# CY8C5868AXI_LP035 register map
File version: 0.1
CY8C58LP
Registers are 32-bit, read-write, no defined reset value unless marked. A register's access mark holds for its fields unless they carry their own. Offsets are from the block's base; lines under a group give offsets from that group; [hi:lo] are bit positions; {n}, {i} and the like mark numbered series; 'fields as' and 'values as' point back to an identical list; <NAME> marks a mode.

## Memory map
0x00000000 b1_critical_timer
0x00000000 b2_critical_timer
0x00000000 LED_Driver2
0x00000000 LED_Driver1
0x00000000 tach_critical_timer
0x00000000 c1_critical_timer
0x00000000 b3_critical_timer
0x00000000 CAN
0x00000000 CAN_Timer

## b1_critical_timer
Base 0x00000000
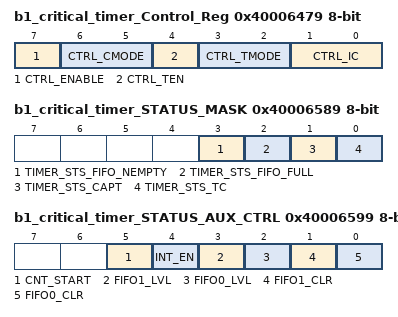
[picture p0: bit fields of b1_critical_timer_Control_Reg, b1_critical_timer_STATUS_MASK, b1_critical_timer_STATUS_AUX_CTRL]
0x40006479 b1_critical_timer_Control_Reg 8-bit — UDB Control Register - Assigned Control Register Value
  [7] CTRL_ENABLE — Enable the Timer
  [6:5] CTRL_CMODE — Capture Mode
  [4] CTRL_TEN — Trigger Enable Bit
  [3:2] CTRL_TMODE — Trigger Mode
  [1:0] CTRL_IC — Interrupt Count
0x40006508 b1_critical_timer_COUNTER 16-bit — UDB.A0 - Current Down Counter Value
0x40006528 b1_critical_timer_PERIOD 16-bit — UDB.D0 - Assigned Period
0x40006589 b1_critical_timer_STATUS_MASK 8-bit — UDB Status bits Interrupt Mask Enable Register
  [3] TIMER_STS_FIFO_NEMPTY ro — FIFO Empty status
  [2] TIMER_STS_FIFO_FULL ro — FIFO Full Status
  [1] TIMER_STS_CAPT ro — Enables the Interrupt on Capture
  [0] TIMER_STS_TC ro — Enables the Interrupt on TC
0x40006599 b1_critical_timer_STATUS_AUX_CTRL 8-bit — UDB Auxilliary Control Register
  [5] CNT_START — FIFO0 clear
    0=E_CNT_START0 (Disable counter); 1=E_CNT_START1 (Enable counter)
  [4] INT_EN
    0=E_INT_EN0 (Interrupt disabled); 1=E_INT_EN1 (Interrupt enabled)
  [3] FIFO1_LVL — FIFO level
    0=E_FIFO_LVL_0 (FIFO LVL: input mode: FIFO not full; output mode: FIFO not empty); 1=E_FIFO_LVL_1 (FIFO LVL: input mode: FIFO at least 1/2 empty; output mode: FIFO at least 1/2 full)
  [2] FIFO0_LVL — FIFO level
    values as FIFO1_LVL
  [1] FIFO1_CLR — FIFO1 clear
    0=E_FIFO_CLR_0 (Normal FIFO operation); 1=E_FIFO_CLR_1 (Clear FIFO state)
  [0] FIFO0_CLR — FIFO0 clear
    values as FIFO1_CLR

## b2_critical_timer
Base 0x00000000
0x4000650A b2_critical_timer_COUNTER 16-bit — UDB.A0 - Current Down Counter Value
0x4000652A b2_critical_timer_PERIOD 16-bit — UDB.D0 - Assigned Period
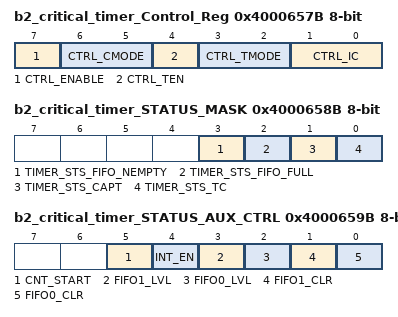
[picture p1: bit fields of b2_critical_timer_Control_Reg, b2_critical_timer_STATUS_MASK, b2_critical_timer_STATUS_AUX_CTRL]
0x4000657B b2_critical_timer_Control_Reg 8-bit — UDB Control Register - Assigned Control Register Value
  [7] CTRL_ENABLE — Enable the Timer
  [6:5] CTRL_CMODE — Capture Mode
  [4] CTRL_TEN — Trigger Enable Bit
  [3:2] CTRL_TMODE — Trigger Mode
  [1:0] CTRL_IC — Interrupt Count
0x4000658B b2_critical_timer_STATUS_MASK 8-bit — UDB Status bits Interrupt Mask Enable Register
  [3] TIMER_STS_FIFO_NEMPTY ro — FIFO Empty status
  [2] TIMER_STS_FIFO_FULL ro — FIFO Full Status
  [1] TIMER_STS_CAPT ro — Enables the Interrupt on Capture
  [0] TIMER_STS_TC ro — Enables the Interrupt on TC
0x4000659B b2_critical_timer_STATUS_AUX_CTRL 8-bit — UDB Auxilliary Control Register
  [5] CNT_START — FIFO0 clear
    0=E_CNT_START0 (Disable counter); 1=E_CNT_START1 (Enable counter)
  [4] INT_EN
    0=E_INT_EN0 (Interrupt disabled); 1=E_INT_EN1 (Interrupt enabled)
  [3] FIFO1_LVL — FIFO level
    0=E_FIFO_LVL_0 (FIFO LVL: input mode: FIFO not full; output mode: FIFO not empty); 1=E_FIFO_LVL_1 (FIFO LVL: input mode: FIFO at least 1/2 empty; output mode: FIFO at least 1/2 full)
  [2] FIFO0_LVL — FIFO level
    values as FIFO1_LVL
  [1] FIFO1_CLR — FIFO1 clear
    0=E_FIFO_CLR_0 (Normal FIFO operation); 1=E_FIFO_CLR_1 (Clear FIFO state)
  [0] FIFO0_CLR — FIFO0 clear
    values as FIFO1_CLR

## LED_Driver2
Base 0x00000000
0x4000640C LED_Driver2_DATA 8-bit — I2C Data Register
  [7:0] data — Read received data or write data to transmit.
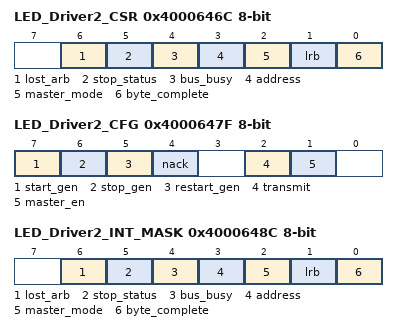
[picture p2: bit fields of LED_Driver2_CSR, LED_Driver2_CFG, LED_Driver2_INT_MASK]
0x4000646C LED_Driver2_CSR 8-bit — I2C Status Register
  [6] lost_arb ro — If set, indicates arbitration was lost (multi-master and multi-master-slave modes).
  [5] stop_status ro — If set, indicates a Stop condition was detected on the bus.
  [4] bus_busy ro — If set, indicates the bus is busy. Data is currently being transmitted or received.
  [3] address ro — Address detection. If set, indicates that an address byte was sent.
  [2] master_mode ro — Indicates that a valid Start condition was generated and a hardware device is operating as bus master.
  [1] lrb ro — Last Received Bit. Indicates the state of the last received bit, which is the ACK/NAK received for the last byte transmitted. Cleared = ACK and set = NAK.
  [0] byte_complete ro — Transmit or receive status since the last read of this register. In Transmit mode this bit indicates that eight bits of data plus ACK/NAK have been transmitted since the last read. In Receive mode this bit indicates that eight bits of data have been received since the last read of this register.
0x4000647F LED_Driver2_CFG 8-bit — I2C Configuration Register
  [7] start_gen — Set to 1 to generate a Start condition on the bus. This bit must be cleared by firmware before initiating the next transaction.
  [6] stop_gen — Set to 1 to generate a Stop condition on the bus. This bit must be cleared by firmware before initiating the next transaction.
  [5] restart_gen — Set to 1 to generate a Restart condition on the bus. This bit must be cleared by firmware after a Restart condition is generated.
  [4] nack — Set to 1 to NAK the next read byte. Clear to ACK next read byte. This bit must be cleared by firmware between bytes.
  [2] transmit — Set to 1 to set the current mode to transmit or clear to 0 to receive a byte of data. This bit must be cleared by firmware before starting the next transmit or receive transaction.
  [1] master_en — Set to 1 to enable the master functionality.
0x4000648C LED_Driver2_INT_MASK 8-bit — I2C Interrupt Enable Mask
  [6] lost_arb — Enables interrupt from the corresponding bit in status register.
  [5] stop_status — Enables interrupt from the corresponding bit in status register.
  [4] bus_busy — Enables interrupt from the corresponding bit in status register.
  [3] address — Enables interrupt from the corresponding bit in status register.
  [2] master_mode — Enables interrupt from the corresponding bit in status register.
  [1] lrb — Enables interrupt from the corresponding bit in status register.
  [0] byte_complete — Enables interrupt from the corresponding bit in status register.
